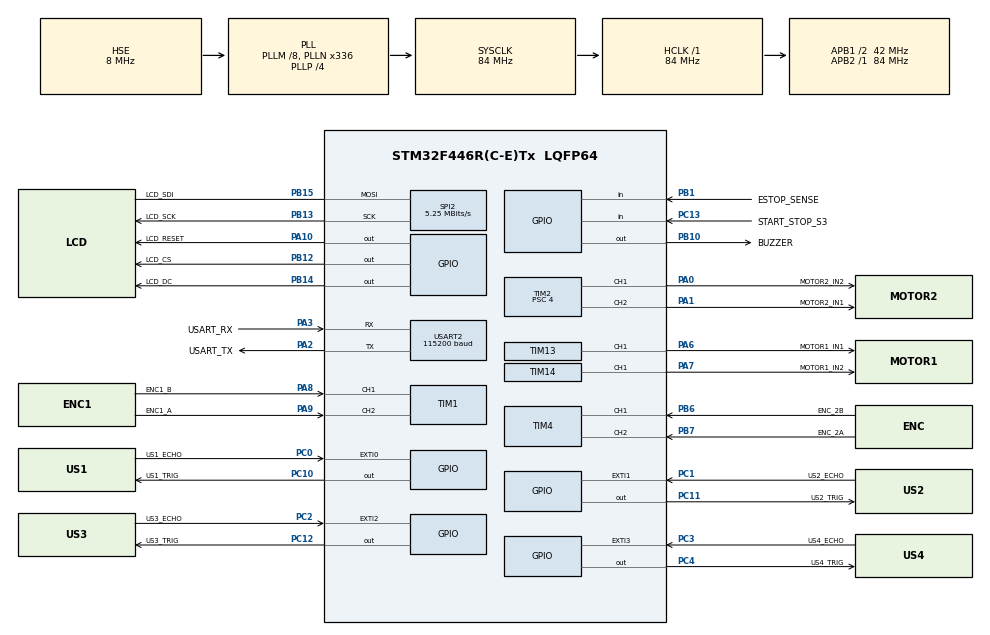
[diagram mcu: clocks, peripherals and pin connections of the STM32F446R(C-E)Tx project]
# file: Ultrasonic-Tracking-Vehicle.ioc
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Mcu.Family=STM32F4
Mcu.Name=STM32F446R(C-E)Tx
Mcu.Package=LQFP64
NVIC.EXTI0_IRQn=true\:1\:0\:false\:false\:true\:true\:true\:true
NVIC.EXTI1_IRQn=true\:1\:0\:false\:false\:true\:true\:true\:true
NVIC.EXTI2_IRQn=true\:1\:0\:false\:false\:true\:true\:true\:true
NVIC.EXTI3_IRQn=true\:1\:0\:false\:false\:true\:true\:true\:true
NVIC.PriorityGroup=NVIC_PRIORITYGROUP_4
PA0-WKUP.GPIO_Label=MOTOR2_IN2
PA0-WKUP.Signal=S_TIM2_CH1_ETR
PA1.GPIO_Label=MOTOR2_IN1
PA1.Signal=S_TIM2_CH2
PA10.GPIO_Label=LCD_RESET
PA10.Signal=GPIO_Output
PA13.GPIO_Label=TMS
PA13.Mode=Serial_Wire
PA13.Signal=SYS_JTMS-SWDIO
PA14.GPIO_Label=TCK
PA14.Mode=Serial_Wire
PA14.Signal=SYS_JTCK-SWCLK
PA2.GPIO_Label=USART_TX
PA2.Mode=Asynchronous
PA2.Signal=USART2_TX
PA3.GPIO_Label=USART_RX
PA3.Mode=Asynchronous
PA3.Signal=USART2_RX
PA6.GPIO_Label=MOTOR1_IN1
PA6.Signal=S_TIM13_CH1
PA7.GPIO_Label=MOTOR1_IN2
PA7.Signal=S_TIM14_CH1
PA8.GPIO_Label=ENC1_B
PA8.Signal=S_TIM1_CH1
PA9.GPIO_Label=ENC1_A
PA9.Signal=S_TIM1_CH2
PB1.GPIO_Label=ESTOP_SENSE
PB1.Signal=GPIO_Input
PB10.GPIO_Label=BUZZER
PB10.Signal=GPIO_Output
PB12.GPIO_Label=LCD_CS
PB12.PinState=GPIO_PIN_SET
PB12.Signal=GPIO_Output
PB13.GPIO_Label=LCD_SCK
PB13.Mode=Simplex_Bidirectional_Master
PB13.Signal=SPI2_SCK
PB14.GPIO_Label=LCD_DC
PB14.Signal=GPIO_Output
PB15.GPIO_Label=LCD_SDI
PB15.Mode=Simplex_Bidirectional_Master
PB15.Signal=SPI2_MOSI
PB6.GPIO_Label=ENC_2B
PB6.Signal=S_TIM4_CH1
PB7.GPIO_Label=ENC_2A
PB7.Signal=S_TIM4_CH2
PC0.GPIO_Label=US1_ECHO
PC0.GPIO_ModeDefaultEXTI=GPIO_MODE_IT_RISING_FALLING
PC0.Signal=GPXTI0
PC1.GPIO_Label=US2_ECHO
PC1.GPIO_ModeDefaultEXTI=GPIO_MODE_IT_RISING_FALLING
PC1.Signal=GPXTI1
PC10.GPIO_Label=US1_TRIG
PC10.Signal=GPIO_Output
PC11.GPIO_Label=US2_TRIG
PC11.Signal=GPIO_Output
PC12.GPIO_Label=US3_TRIG
PC12.Signal=GPIO_Output
PC13.GPIO_Label=START_STOP_S3
PC13.Signal=GPIO_Input
PC2.GPIO_Label=US3_ECHO
PC2.GPIO_ModeDefaultEXTI=GPIO_MODE_IT_RISING_FALLING
PC2.Signal=GPXTI2
PC3.GPIO_Label=US4_ECHO
PC3.GPIO_ModeDefaultEXTI=GPIO_MODE_IT_RISING_FALLING
PC3.Signal=GPXTI3
PC4.GPIO_Label=US4_TRIG
PC4.Signal=GPIO_Output
PH0-OSC_IN.Mode=HSE-External-Clock-Source
PH0-OSC_IN.Signal=RCC_OSC_IN
PH1-OSC_OUT.Mode=HSE-External-Clock-Source
PH1-OSC_OUT.Signal=RCC_OSC_OUT
ProjectManager.HeapSize=0x200
ProjectManager.StackSize=0x400
ProjectManager.TargetToolchain=STM32CubeIDE
RCC.AHBFreq_Value=84000000
RCC.APB1CLKDivider=RCC_HCLK_DIV2
RCC.APB1Freq_Value=42000000
RCC.APB1TimFreq_Value=84000000
RCC.APB2CLKDivider=RCC_HCLK_DIV1
RCC.APB2Freq_Value=84000000
RCC.APB2TimFreq_Value=84000000
RCC.CortexFreq_Value=84000000
RCC.FLatency=FLASH_LATENCY_2
RCC.HCLKFreq_Value=84000000
RCC.HSE_VALUE=8000000
RCC.PLLM=8
RCC.PLLN=336
RCC.PLLP=RCC_PLLP_DIV4
RCC.PLLQ=7
RCC.PLLSourceVirtual=RCC_PLLSOURCE_HSE
RCC.SYSCLKFreq_VALUE=84000000
RCC.SYSCLKSource=RCC_SYSCLKSOURCE_PLLCLK
RCC.VCOOutputFreq_Value=336000000
SH.S_TIM13_CH1.0=TIM13_CH1,PWM Generation1 CH1
SH.S_TIM14_CH1.0=TIM14_CH1,PWM Generation1 CH1
SH.S_TIM1_CH1.0=TIM1_CH1,Encoder_Interface
SH.S_TIM1_CH2.0=TIM1_CH2,Encoder_Interface
SH.S_TIM2_CH1_ETR.0=TIM2_CH1,PWM Generation1 CH1
SH.S_TIM2_CH2.0=TIM2_CH2,PWM Generation2 CH2
SH.S_TIM4_CH1.0=TIM4_CH1,Encoder_Interface
SH.S_TIM4_CH2.0=TIM4_CH2,Encoder_Interface
SPI2.BaudRatePrescaler=SPI_BAUDRATEPRESCALER_8
SPI2.CalculateBaudRate=5.25 MBits/s
SPI2.Direction=SPI_DIRECTION_1LINE
SPI2.Mode=SPI_MODE_MASTER
SPI2.VirtualType=VM_MASTER
TIM1.ClockDivision=TIM_CLOCKDIVISION_DIV1
TIM1.EncoderMode=TIM_ENCODERMODE_TI12
TIM1.IC1Filter=0
TIM13.AutoReloadPreload=TIM_AUTORELOAD_PRELOAD_ENABLE
TIM13.Channel=TIM_CHANNEL_1
TIM13.Period=55999
TIM13.Prescaler=4
TIM14.AutoReloadPreload=TIM_AUTORELOAD_PRELOAD_ENABLE
TIM14.Channel=TIM_CHANNEL_1
TIM14.Period=55999
TIM14.Prescaler=4
TIM2.Channel-PWM\ Generation1\ CH1=TIM_CHANNEL_1
TIM2.Channel-PWM\ Generation2\ CH2=TIM_CHANNEL_2
TIM2.Period=55999
TIM2.Prescaler=4
TIM4.EncoderMode=TIM_ENCODERMODE_TI12
TIM5.Period=4294967295
TIM5.Prescaler=83
USART2.BaudRate=115200
USART2.VirtualMode=VM_ASYNC
VP_TIM13_VS_ClockSourceINT.Mode=Enable_Timer
VP_TIM14_VS_ClockSourceINT.Mode=Enable_Timer
VP_TIM5_VS_ClockSourceINT.Mode=Internal
board=custom

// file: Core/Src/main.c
/* USER CODE BEGIN Header */
/**
  ******************************************************************************
  * @file           : main.c
  * @brief          : Main program body
  ******************************************************************************
  * @attention
  *
  * Copyright (c) 2026 STMicroelectronics.
  * All rights reserved.
  *
  * This software is licensed under terms that can be found in the LICENSE file
  * in the root directory of this software component.
  * If no LICENSE file comes with this software, it is provided AS-IS.
  *
  ******************************************************************************
  */
/* USER CODE END Header */
#include "main.h"

/* USER CODE BEGIN Includes */
#include "ultrasonic.h"
#include <stdio.h>
#include "motor_encoder_test.h"

/* USER CODE END Includes */

SPI_HandleTypeDef hspi2;

TIM_HandleTypeDef htim1;
TIM_HandleTypeDef htim2;
TIM_HandleTypeDef htim4;
TIM_HandleTypeDef htim5;
TIM_HandleTypeDef htim13;
TIM_HandleTypeDef htim14;

UART_HandleTypeDef huart2;

void SystemClock_Config(void);
static void MX_GPIO_Init(void);
static void MX_SPI2_Init(void);
static void MX_TIM5_Init(void);
static void MX_USART2_UART_Init(void);
static void MX_TIM13_Init(void);
static void MX_TIM14_Init(void);
static void MX_TIM4_Init(void);
static void MX_TIM1_Init(void);
static void MX_TIM2_Init(void);

int main(void)
{

  /* MCU Configuration--------------------------------------------------------*/

  /* Reset of all peripherals, Initializes the Flash interface and the Systick. */
  HAL_Init();

  /* Configure the system clock */
  SystemClock_Config();

  /* Initialize all configured peripherals */
  MX_GPIO_Init();
  MX_SPI2_Init();
  MX_TIM5_Init();
  MX_USART2_UART_Init();
  MX_TIM13_Init();
  MX_TIM14_Init();
  MX_TIM4_Init();
  MX_TIM1_Init();
  MX_TIM2_Init();
  /* USER CODE BEGIN 2 */
  /* 動作確認メニュー（USART2 115200bps）。3: 超音波の本処理、5〜9: モータ・エンコーダ・ブザー・液晶の確認。戻らない */
  MotorEncoderTest_Run();

  /* USER CODE END 2 */

  /* Infinite loop */
  while (1)
  {

  }
}

void SystemClock_Config(void)
{
  RCC_OscInitTypeDef RCC_OscInitStruct = {0};
  RCC_ClkInitTypeDef RCC_ClkInitStruct = {0};

  /** Configure the main internal regulator output voltage
  */
  __HAL_RCC_PWR_CLK_ENABLE();
  __HAL_PWR_VOLTAGESCALING_CONFIG(PWR_REGULATOR_VOLTAGE_SCALE3);

  /** Initializes the RCC Oscillators according to the specified parameters
  * in the RCC_OscInitTypeDef structure.
  */
  RCC_OscInitStruct.OscillatorType = RCC_OSCILLATORTYPE_HSE;
  RCC_OscInitStruct.HSEState = RCC_HSE_BYPASS;
  RCC_OscInitStruct.PLL.PLLState = RCC_PLL_ON;
  RCC_OscInitStruct.PLL.PLLSource = RCC_PLLSOURCE_HSE;
  RCC_OscInitStruct.PLL.PLLM = 8;
  RCC_OscInitStruct.PLL.PLLN = 336;
  RCC_OscInitStruct.PLL.PLLP = RCC_PLLP_DIV4;
  RCC_OscInitStruct.PLL.PLLQ = 7;
  RCC_OscInitStruct.PLL.PLLR = 2;
  if (HAL_RCC_OscConfig(&RCC_OscInitStruct) != HAL_OK)
  {
    Error_Handler();
  }

  /** Initializes the CPU, AHB and APB buses clocks
  */
  RCC_ClkInitStruct.ClockType = RCC_CLOCKTYPE_HCLK|RCC_CLOCKTYPE_SYSCLK
                              |RCC_CLOCKTYPE_PCLK1|RCC_CLOCKTYPE_PCLK2;
  RCC_ClkInitStruct.SYSCLKSource = RCC_SYSCLKSOURCE_PLLCLK;
  RCC_ClkInitStruct.AHBCLKDivider = RCC_SYSCLK_DIV1;
  RCC_ClkInitStruct.APB1CLKDivider = RCC_HCLK_DIV2;
  RCC_ClkInitStruct.APB2CLKDivider = RCC_HCLK_DIV1;

  if (HAL_RCC_ClockConfig(&RCC_ClkInitStruct, FLASH_LATENCY_2) != HAL_OK)
  {
    Error_Handler();
  }
}

static void MX_SPI2_Init(void)
{

  /* SPI2 parameter configuration*/
  hspi2.Instance = SPI2;
  hspi2.Init.Mode = SPI_MODE_MASTER;
  hspi2.Init.Direction = SPI_DIRECTION_1LINE;
  hspi2.Init.DataSize = SPI_DATASIZE_8BIT;
  hspi2.Init.CLKPolarity = SPI_POLARITY_LOW;
  hspi2.Init.CLKPhase = SPI_PHASE_1EDGE;
  hspi2.Init.NSS = SPI_NSS_SOFT;
  hspi2.Init.BaudRatePrescaler = SPI_BAUDRATEPRESCALER_8;
  hspi2.Init.FirstBit = SPI_FIRSTBIT_MSB;
  hspi2.Init.TIMode = SPI_TIMODE_DISABLE;
  hspi2.Init.CRCCalculation = SPI_CRCCALCULATION_DISABLE;
  hspi2.Init.CRCPolynomial = 10;
  if (HAL_SPI_Init(&hspi2) != HAL_OK)
  {
    Error_Handler();
  }

}

static void MX_TIM1_Init(void)
{

  TIM_Encoder_InitTypeDef sConfig = {0};
  TIM_MasterConfigTypeDef sMasterConfig = {0};

  htim1.Instance = TIM1;
  htim1.Init.Prescaler = 0;
  htim1.Init.CounterMode = TIM_COUNTERMODE_UP;
  htim1.Init.Period = 65535;
  htim1.Init.ClockDivision = TIM_CLOCKDIVISION_DIV1;
  htim1.Init.RepetitionCounter = 0;
  htim1.Init.AutoReloadPreload = TIM_AUTORELOAD_PRELOAD_DISABLE;
  sConfig.EncoderMode = TIM_ENCODERMODE_TI12;
  sConfig.IC1Polarity = TIM_ICPOLARITY_RISING;
  sConfig.IC1Selection = TIM_ICSELECTION_DIRECTTI;
  sConfig.IC1Prescaler = TIM_ICPSC_DIV1;
  sConfig.IC1Filter = 0;
  sConfig.IC2Polarity = TIM_ICPOLARITY_RISING;
  sConfig.IC2Selection = TIM_ICSELECTION_DIRECTTI;
  sConfig.IC2Prescaler = TIM_ICPSC_DIV1;
  sConfig.IC2Filter = 0;
  if (HAL_TIM_Encoder_Init(&htim1, &sConfig) != HAL_OK)
  {
    Error_Handler();
  }
  sMasterConfig.MasterOutputTrigger = TIM_TRGO_RESET;
  sMasterConfig.MasterSlaveMode = TIM_MASTERSLAVEMODE_DISABLE;
  if (HAL_TIMEx_MasterConfigSynchronization(&htim1, &sMasterConfig) != HAL_OK)
  {
    Error_Handler();
  }

}

static void MX_TIM2_Init(void)
{

  TIM_MasterConfigTypeDef sMasterConfig = {0};
  TIM_OC_InitTypeDef sConfigOC = {0};

  htim2.Instance = TIM2;
  htim2.Init.Prescaler = 4;
  htim2.Init.CounterMode = TIM_COUNTERMODE_UP;
  htim2.Init.Period = 55999;
  htim2.Init.ClockDivision = TIM_CLOCKDIVISION_DIV1;
  htim2.Init.AutoReloadPreload = TIM_AUTORELOAD_PRELOAD_DISABLE;
  if (HAL_TIM_PWM_Init(&htim2) != HAL_OK)
  {
    Error_Handler();
  }
  sMasterConfig.MasterOutputTrigger = TIM_TRGO_RESET;
  sMasterConfig.MasterSlaveMode = TIM_MASTERSLAVEMODE_DISABLE;
  if (HAL_TIMEx_MasterConfigSynchronization(&htim2, &sMasterConfig) != HAL_OK)
  {
    Error_Handler();
  }
  sConfigOC.OCMode = TIM_OCMODE_PWM1;
  sConfigOC.Pulse = 0;
  sConfigOC.OCPolarity = TIM_OCPOLARITY_HIGH;
  sConfigOC.OCFastMode = TIM_OCFAST_DISABLE;
  if (HAL_TIM_PWM_ConfigChannel(&htim2, &sConfigOC, TIM_CHANNEL_1) != HAL_OK)
  {
    Error_Handler();
  }
  if (HAL_TIM_PWM_ConfigChannel(&htim2, &sConfigOC, TIM_CHANNEL_2) != HAL_OK)
  {
    Error_Handler();
  }
  HAL_TIM_MspPostInit(&htim2);

}

static void MX_TIM4_Init(void)
{

  TIM_Encoder_InitTypeDef sConfig = {0};
  TIM_MasterConfigTypeDef sMasterConfig = {0};

  htim4.Instance = TIM4;
  htim4.Init.Prescaler = 0;
  htim4.Init.CounterMode = TIM_COUNTERMODE_UP;
  htim4.Init.Period = 65535;
  htim4.Init.ClockDivision = TIM_CLOCKDIVISION_DIV1;
  htim4.Init.AutoReloadPreload = TIM_AUTORELOAD_PRELOAD_DISABLE;
  sConfig.EncoderMode = TIM_ENCODERMODE_TI12;
  sConfig.IC1Polarity = TIM_ICPOLARITY_RISING;
  sConfig.IC1Selection = TIM_ICSELECTION_DIRECTTI;
  sConfig.IC1Prescaler = TIM_ICPSC_DIV1;
  sConfig.IC1Filter = 0;
  sConfig.IC2Polarity = TIM_ICPOLARITY_RISING;
  sConfig.IC2Selection = TIM_ICSELECTION_DIRECTTI;
  sConfig.IC2Prescaler = TIM_ICPSC_DIV1;
  sConfig.IC2Filter = 0;
  if (HAL_TIM_Encoder_Init(&htim4, &sConfig) != HAL_OK)
  {
    Error_Handler();
  }
  sMasterConfig.MasterOutputTrigger = TIM_TRGO_RESET;
  sMasterConfig.MasterSlaveMode = TIM_MASTERSLAVEMODE_DISABLE;
  if (HAL_TIMEx_MasterConfigSynchronization(&htim4, &sMasterConfig) != HAL_OK)
  {
    Error_Handler();
  }

}

static void MX_TIM5_Init(void)
{

  TIM_ClockConfigTypeDef sClockSourceConfig = {0};
  TIM_MasterConfigTypeDef sMasterConfig = {0};

  htim5.Instance = TIM5;
  htim5.Init.Prescaler = 83;
  htim5.Init.CounterMode = TIM_COUNTERMODE_UP;
  htim5.Init.Period = 4294967295;
  htim5.Init.ClockDivision = TIM_CLOCKDIVISION_DIV1;
  htim5.Init.AutoReloadPreload = TIM_AUTORELOAD_PRELOAD_DISABLE;
  if (HAL_TIM_Base_Init(&htim5) != HAL_OK)
  {
    Error_Handler();
  }
  sClockSourceConfig.ClockSource = TIM_CLOCKSOURCE_INTERNAL;
  if (HAL_TIM_ConfigClockSource(&htim5, &sClockSourceConfig) != HAL_OK)
  {
    Error_Handler();
  }
  sMasterConfig.MasterOutputTrigger = TIM_TRGO_RESET;
  sMasterConfig.MasterSlaveMode = TIM_MASTERSLAVEMODE_DISABLE;
  if (HAL_TIMEx_MasterConfigSynchronization(&htim5, &sMasterConfig) != HAL_OK)
  {
    Error_Handler();
  }

}

static void MX_TIM13_Init(void)
{

  TIM_OC_InitTypeDef sConfigOC = {0};

  htim13.Instance = TIM13;
  htim13.Init.Prescaler = 4;
  htim13.Init.CounterMode = TIM_COUNTERMODE_UP;
  htim13.Init.Period = 55999;
  htim13.Init.ClockDivision = TIM_CLOCKDIVISION_DIV1;
  htim13.Init.AutoReloadPreload = TIM_AUTORELOAD_PRELOAD_ENABLE;
  if (HAL_TIM_Base_Init(&htim13) != HAL_OK)
  {
    Error_Handler();
  }
  if (HAL_TIM_PWM_Init(&htim13) != HAL_OK)
  {
    Error_Handler();
  }
  sConfigOC.OCMode = TIM_OCMODE_PWM1;
  sConfigOC.Pulse = 0;
  sConfigOC.OCPolarity = TIM_OCPOLARITY_HIGH;
  sConfigOC.OCFastMode = TIM_OCFAST_DISABLE;
  if (HAL_TIM_PWM_ConfigChannel(&htim13, &sConfigOC, TIM_CHANNEL_1) != HAL_OK)
  {
    Error_Handler();
  }
  HAL_TIM_MspPostInit(&htim13);

}

static void MX_TIM14_Init(void)
{

  TIM_OC_InitTypeDef sConfigOC = {0};

  htim14.Instance = TIM14;
  htim14.Init.Prescaler = 4;
  htim14.Init.CounterMode = TIM_COUNTERMODE_UP;
  htim14.Init.Period = 55999;
  htim14.Init.ClockDivision = TIM_CLOCKDIVISION_DIV1;
  htim14.Init.AutoReloadPreload = TIM_AUTORELOAD_PRELOAD_ENABLE;
  if (HAL_TIM_Base_Init(&htim14) != HAL_OK)
  {
    Error_Handler();
  }
  if (HAL_TIM_PWM_Init(&htim14) != HAL_OK)
  {
    Error_Handler();
  }
  sConfigOC.OCMode = TIM_OCMODE_PWM1;
  sConfigOC.Pulse = 0;
  sConfigOC.OCPolarity = TIM_OCPOLARITY_HIGH;
  sConfigOC.OCFastMode = TIM_OCFAST_DISABLE;
  if (HAL_TIM_PWM_ConfigChannel(&htim14, &sConfigOC, TIM_CHANNEL_1) != HAL_OK)
  {
    Error_Handler();
  }
  HAL_TIM_MspPostInit(&htim14);

}

static void MX_USART2_UART_Init(void)
{

  huart2.Instance = USART2;
  huart2.Init.BaudRate = 115200;
  huart2.Init.WordLength = UART_WORDLENGTH_8B;
  huart2.Init.StopBits = UART_STOPBITS_1;
  huart2.Init.Parity = UART_PARITY_NONE;
  huart2.Init.Mode = UART_MODE_TX_RX;
  huart2.Init.HwFlowCtl = UART_HWCONTROL_NONE;
  huart2.Init.OverSampling = UART_OVERSAMPLING_16;
  if (HAL_UART_Init(&huart2) != HAL_OK)
  {
    Error_Handler();
  }

}

static void MX_GPIO_Init(void)
{
  GPIO_InitTypeDef GPIO_InitStruct = {0};

  /* GPIO Ports Clock Enable */
  __HAL_RCC_GPIOC_CLK_ENABLE();
  __HAL_RCC_GPIOH_CLK_ENABLE();
  __HAL_RCC_GPIOA_CLK_ENABLE();
  __HAL_RCC_GPIOB_CLK_ENABLE();

  /*Configure GPIO pin Output Level */
  HAL_GPIO_WritePin(GPIOC, US4_TRIG_Pin|US1_TRIG_Pin|US2_TRIG_Pin|US3_TRIG_Pin, GPIO_PIN_RESET);

  /*Configure GPIO pin Output Level */
  HAL_GPIO_WritePin(GPIOB, BUZZER_Pin|LCD_DC_Pin, GPIO_PIN_RESET);

  /*Configure GPIO pin Output Level */
  HAL_GPIO_WritePin(LCD_CS_GPIO_Port, LCD_CS_Pin, GPIO_PIN_SET);

  /*Configure GPIO pin Output Level */
  HAL_GPIO_WritePin(LCD_RESET_GPIO_Port, LCD_RESET_Pin, GPIO_PIN_RESET);

  /*Configure GPIO pin : START_STOP_S3_Pin */
  GPIO_InitStruct.Pin = START_STOP_S3_Pin;
  GPIO_InitStruct.Mode = GPIO_MODE_INPUT;
  GPIO_InitStruct.Pull = GPIO_NOPULL;
  HAL_GPIO_Init(START_STOP_S3_GPIO_Port, &GPIO_InitStruct);

  /*Configure GPIO pins : US1_ECHO_Pin US2_ECHO_Pin US3_ECHO_Pin US4_ECHO_Pin */
  GPIO_InitStruct.Pin = US1_ECHO_Pin|US2_ECHO_Pin|US3_ECHO_Pin|US4_ECHO_Pin;
  GPIO_InitStruct.Mode = GPIO_MODE_IT_RISING_FALLING;
  GPIO_InitStruct.Pull = GPIO_NOPULL;
  HAL_GPIO_Init(GPIOC, &GPIO_InitStruct);

  /*Configure GPIO pins : US4_TRIG_Pin US1_TRIG_Pin US2_TRIG_Pin US3_TRIG_Pin */
  GPIO_InitStruct.Pin = US4_TRIG_Pin|US1_TRIG_Pin|US2_TRIG_Pin|US3_TRIG_Pin;
  GPIO_InitStruct.Mode = GPIO_MODE_OUTPUT_PP;
  GPIO_InitStruct.Pull = GPIO_NOPULL;
  GPIO_InitStruct.Speed = GPIO_SPEED_FREQ_LOW;
  HAL_GPIO_Init(GPIOC, &GPIO_InitStruct);

  /*Configure GPIO pins : BUZZER_Pin LCD_CS_Pin LCD_DC_Pin */
  GPIO_InitStruct.Pin = BUZZER_Pin|LCD_CS_Pin|LCD_DC_Pin;
  GPIO_InitStruct.Mode = GPIO_MODE_OUTPUT_PP;
  GPIO_InitStruct.Pull = GPIO_NOPULL;
  GPIO_InitStruct.Speed = GPIO_SPEED_FREQ_LOW;
  HAL_GPIO_Init(GPIOB, &GPIO_InitStruct);

  /*Configure GPIO pin : LCD_RESET_Pin */
  GPIO_InitStruct.Pin = LCD_RESET_Pin;
  GPIO_InitStruct.Mode = GPIO_MODE_OUTPUT_PP;
  GPIO_InitStruct.Pull = GPIO_NOPULL;
  GPIO_InitStruct.Speed = GPIO_SPEED_FREQ_LOW;
  HAL_GPIO_Init(LCD_RESET_GPIO_Port, &GPIO_InitStruct);

  /* EXTI interrupt init*/
  HAL_NVIC_SetPriority(EXTI0_IRQn, 1, 0);
  HAL_NVIC_EnableIRQ(EXTI0_IRQn);

  HAL_NVIC_SetPriority(EXTI1_IRQn, 1, 0);
  HAL_NVIC_EnableIRQ(EXTI1_IRQn);

  HAL_NVIC_SetPriority(EXTI2_IRQn, 1, 0);
  HAL_NVIC_EnableIRQ(EXTI2_IRQn);

  HAL_NVIC_SetPriority(EXTI3_IRQn, 1, 0);
  HAL_NVIC_EnableIRQ(EXTI3_IRQn);

}

/* USER CODE BEGIN 4 */
/* printf の出力先を USART2（ST-LINK の仮想COMポート）にする。
 * syscalls.c の _write が 1文字ずつ __io_putchar を呼ぶ。
 * huart2 は CubeMX が生成する（再生成が必要）。 */
int __io_putchar(int ch)
{
  uint8_t c = (uint8_t)ch;
  HAL_UART_Transmit(&huart2, &c, 1, 10);
  return ch;
}

/* EXTI（外部ピン割り込み）が起きるたびに HAL から呼ばれる関数。
 * Echo ピン（PC0〜PC3）の変化を超音波ドライバに渡す。 */
void HAL_GPIO_EXTI_Callback(uint16_t GPIO_Pin)
{
  Ultrasonic_EXTI_Callback(GPIO_Pin);
}

/* USER CODE END 4 */

void Error_Handler(void)
{
  __disable_irq();
  while (1)
  {
  }
}
